# cslr_plicc55x_001 register map
Vendor: Texas Instruments
Peripheral module from a debugger description file.
Registers are 16-bit, access per field, reset 0x0 unless marked. A register's access mark holds for its fields unless they carry their own. Offsets are as the file gives them; lines under a group give offsets from that group; [hi:lo] are bit positions; {n}, {i} and the like mark numbered series; 'fields as' and 'values as' point back to an identical list; <NAME> marks a mode.

## PLIC — Power management / Idle configurations
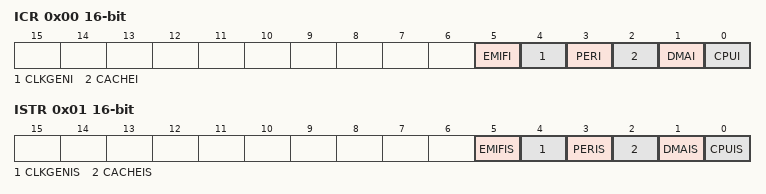
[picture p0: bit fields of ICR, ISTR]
0x00 ICR — Idle Configuration Register
  [5] EMIFI rw — EMIF-domain idle configuration bit.
    0=EMIF will be active; 1=EMIF will be idle
  [4] CLKGENI rw — CLKGEN-domain idle configuration bit.
    0=Clock generator will be active; 1=Clock generator will be idle
  [3] PERI rw — PERIPH-domain idle configuration bit.
    0=All peripherals in the domain will be active; 1=For each peripheral in the domain: If the idle enable bit is 1, the peripheral will be in its idle mode. If the idle enable bit is 0, the peripheral will be active.
  [2] CACHEI rw — CACHE-domain idle configuration bit.
    0=Cache will be active; 1=Cache will be idle
  [1] DMAI rw — DMA-domain idle configuration bit.
    0=DMA controller will be active; 1=DMA controller will be idle
  [0] CPUI rw — CPU-domain idle configuration bit.
    0=CPU will be active; 1=CPU will be idle
0x01 ISTR ro — Idle Status Register
  [5] EMIFIS — EMIF-domain idle status bit.
    0=EMIF is active; 1=EMIF is idle
  [4] CLKGENIS — CLKGEN-domain idle status bit.
    0=Clock generator is active; 1=Clock generator is idle
  [3] PERIS — PERIPH-domain idle status bit.
    0=All peripherals in the domain are active; 1=For each peripheral in the domain: If the idle enable bit is 1, the peripheral is idle. If the idle enable bit is 0, the peripheral is active.
  [2] CACHEIS — CACHE-domain idle status bit.
    0=Cache is active; 1=Cache is idle
  [1] DMAIS — DMA-domain idle status bit.
    0=DMA controller is active; 1=DMA controller is idle
  [0] CPUIS — CPU-domain idle status bit.
    0=CPU is active; 1=CPU is idle
